# SYSCTRL_PADCONF_CORE register map
Vendor: Texas Instruments
Registers are 32-bit, access per field, reset 0x10F010F unless marked. A register's access mark holds for its fields unless they carry their own. Offsets are as the file gives them; [hi:lo] are bit positions; 'fields as' and 'values as' point back to an identical list.

## SYSCTRL_PADCONF_CORE (part 5 of 10)
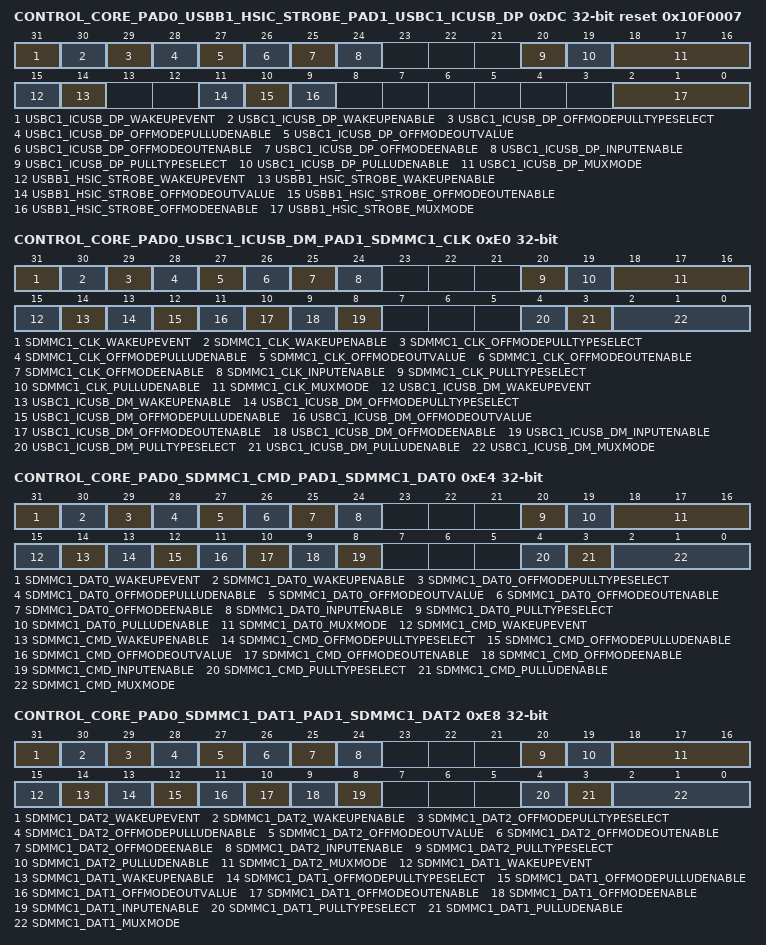
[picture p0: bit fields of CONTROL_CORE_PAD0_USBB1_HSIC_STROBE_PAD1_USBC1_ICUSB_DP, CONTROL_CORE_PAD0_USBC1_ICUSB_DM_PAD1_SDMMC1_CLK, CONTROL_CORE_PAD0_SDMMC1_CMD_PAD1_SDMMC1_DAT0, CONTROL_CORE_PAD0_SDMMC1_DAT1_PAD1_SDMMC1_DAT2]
0xDC CONTROL_CORE_PAD0_USBB1_HSIC_STROBE_PAD1_USBC1_ICUSB_DP reset 0x10F0007 — Register control for Pads usbb1_hsic_strobe and usbc1_icusb_dp Access conditions. Read: unrestricted, Write: unrestricted
  [31] USBC1_ICUSB_DP_WAKEUPEVENT ro — Pad_x wake-up event status latched in the IO
    0=USBC1_ICUSB_DP_WAKEUPEVENT_0_r (No wake-up event occurred); 1=USBC1_ICUSB_DP_WAKEUPEVENT_1_r (A wake-up event occurred)
  [30] USBC1_ICUSB_DP_WAKEUPENABLE rw — Input pad wake-up enable (and OFF mode input enable value)
    0=wake-up detection is disabled; 1=wake-up detection is enabled
  [29] USBC1_ICUSB_DP_OFFMODEPULLTYPESELECT rw — OffMode mode pullup/down selection for pad usbc1_icusb_dp
    0=Offmode pulldown selected; 1=Offmode pullup selected
  [28] USBC1_ICUSB_DP_OFFMODEPULLUDENABLE rw — OffMode mode pullup/down enable for pad usbc1_icusb_dp
    0=Offmode pullup/down disabled; 1=Offmode pullup/down enabled
  [27] USBC1_ICUSB_DP_OFFMODEOUTVALUE rw — OffMode mode output value for pad usbc1_icusb_dp
    0=Set value at 0; 1=Set value at 1
  [26] USBC1_ICUSB_DP_OFFMODEOUTENABLE rw — OffMode mode output enable value for pad usbc1_icusb_dp. This is an active low signal
    0=Output enable; 1=Output disable
  [25] USBC1_ICUSB_DP_OFFMODEENABLE rw — OffMode mode override control for pad usbc1_icusb_dp
    0=I/O state keeps its previous state when OFF mode is active; 1=I/O state is forced to OFF mode value when OFF mode is active
  [24] USBC1_ICUSB_DP_INPUTENABLE rw — Input enable value for pad usbc1_icusb_dp
    0=Input buffer of I/O cell is disabled; 1=Input buffer of I/O cell is enabled
  [20] USBC1_ICUSB_DP_PULLTYPESELECT rw — pullup/down selection for pad usbc1_icusb_dp
    0=pulldown selected; 1=pullup selected
  [19] USBC1_ICUSB_DP_PULLUDENABLE rw — pullup/down enable for pad usbc1_icusb_dp
    0=pullup/down disabled; 1=pullup/down enabled
  [18:16] USBC1_ICUSB_DP_MUXMODE rw — Functional multiplexing selection for pad usbc1_icusb_dp
    0=Select usbc1_icusb_dp; 3=Select gpio_98; 7=Select safe_mode
  [15] USBB1_HSIC_STROBE_WAKEUPEVENT ro — Pad_x wake-up event status latched in the IO
    0=USBB1_HSIC_STROBE_WAKEUPEVENT_0_r (No wake-up event occurred); 1=USBB1_HSIC_STROBE_WAKEUPEVENT_1_r (A wake-up event occurred)
  [14] USBB1_HSIC_STROBE_WAKEUPENABLE rw — Input pad wake-up enable (and OFF mode input enable value)
    values as USBC1_ICUSB_DP_WAKEUPENABLE
  [11] USBB1_HSIC_STROBE_OFFMODEOUTVALUE rw — OffMode mode output value for pad usbb1_hsic_strobe
    0=Set value at 0; 1=Set value at 1
  [10] USBB1_HSIC_STROBE_OFFMODEOUTENABLE rw — OffMode mode output enable value for pad usbb1_hsic_strobe. This is an active low signal
    0=Output enable; 1=Output disable
  [9] USBB1_HSIC_STROBE_OFFMODEENABLE rw — OffMode mode override control for pad usbb1_hsic_strobe
    values as USBC1_ICUSB_DP_OFFMODEENABLE
  [2:0] USBB1_HSIC_STROBE_MUXMODE rw — Functional multiplexing selection for pad usbb1_hsic_strobe
    0=Select usbb1_hsic_strobe; 3=Select gpio_97; 7=Select safe_mode
0xE0 CONTROL_CORE_PAD0_USBC1_ICUSB_DM_PAD1_SDMMC1_CLK — Register control for Pads usbc1_icusb_dm and sdmmc1_clk Access conditions. Read: unrestricted, Write: unrestricted
  [31] SDMMC1_CLK_WAKEUPEVENT ro — Pad_x wake-up event status latched in the IO
    0=SDMMC1_CLK_WAKEUPEVENT_0_r (No wake-up event occurred); 1=SDMMC1_CLK_WAKEUPEVENT_1_r (A wake-up event occurred)
  [30] SDMMC1_CLK_WAKEUPENABLE rw — Input pad wake-up enable (and OFF mode input enable value)
    values as CONTROL_CORE_PAD0_USBB1_HSIC_STROBE_PAD1_USBC1_ICUSB_DP.USBC1_ICUSB_DP_WAKEUPENABLE
  [29] SDMMC1_CLK_OFFMODEPULLTYPESELECT rw — OffMode mode pullup/down selection for pad sdmmc1_clk
    0=Offmode pulldown selected; 1=Offmode pullup selected
  [28] SDMMC1_CLK_OFFMODEPULLUDENABLE rw — OffMode mode pullup/down enable for pad sdmmc1_clk
    values as CONTROL_CORE_PAD0_USBB1_HSIC_STROBE_PAD1_USBC1_ICUSB_DP.USBC1_ICUSB_DP_OFFMODEPULLUDENABLE
  [27] SDMMC1_CLK_OFFMODEOUTVALUE rw — OffMode mode output value for pad sdmmc1_clk
    0=Set value at 0; 1=Set value at 1
  [26] SDMMC1_CLK_OFFMODEOUTENABLE rw — OffMode mode output enable value for pad sdmmc1_clk. This is an active low signal
    0=Output enable; 1=Output disable
  [25] SDMMC1_CLK_OFFMODEENABLE rw — OffMode mode override control for pad sdmmc1_clk
    values as CONTROL_CORE_PAD0_USBB1_HSIC_STROBE_PAD1_USBC1_ICUSB_DP.USBC1_ICUSB_DP_OFFMODEENABLE
  [24] SDMMC1_CLK_INPUTENABLE rw — Input enable value for pad sdmmc1_clk
    values as CONTROL_CORE_PAD0_USBB1_HSIC_STROBE_PAD1_USBC1_ICUSB_DP.USBC1_ICUSB_DP_INPUTENABLE
  [20] SDMMC1_CLK_PULLTYPESELECT rw — pullup/down selection for pad sdmmc1_clk
    0=pulldown selected; 1=pullup selected
  [19] SDMMC1_CLK_PULLUDENABLE rw — pullup/down enable for pad sdmmc1_clk
    0=pullup/down disabled; 1=pullup/down enabled
  [18:16] SDMMC1_CLK_MUXMODE rw — Functional multiplexing selection for pad sdmmc1_clk
    0=Select sdmmc1_clk; 2=Select dpm_emu19; 3=Select gpio_100; 7=Select safe_mode
  [15] USBC1_ICUSB_DM_WAKEUPEVENT ro — Pad_x wake-up event status latched in the IO
    0=USBC1_ICUSB_DM_WAKEUPEVENT_0_r (No wake-up event occurred); 1=USBC1_ICUSB_DM_WAKEUPEVENT_1_r (A wake-up event occurred)
  [14] USBC1_ICUSB_DM_WAKEUPENABLE rw — Input pad wake-up enable (and OFF mode input enable value)
    values as CONTROL_CORE_PAD0_USBB1_HSIC_STROBE_PAD1_USBC1_ICUSB_DP.USBC1_ICUSB_DP_WAKEUPENABLE
  [13] USBC1_ICUSB_DM_OFFMODEPULLTYPESELECT rw — OffMode mode pullup/down selection for pad usbc1_icusb_dm
    0=Offmode pulldown selected; 1=Offmode pullup selected
  [12] USBC1_ICUSB_DM_OFFMODEPULLUDENABLE rw — OffMode mode pullup/down enable for pad usbc1_icusb_dm
    values as CONTROL_CORE_PAD0_USBB1_HSIC_STROBE_PAD1_USBC1_ICUSB_DP.USBC1_ICUSB_DP_OFFMODEPULLUDENABLE
  [11] USBC1_ICUSB_DM_OFFMODEOUTVALUE rw — OffMode mode output value for pad usbc1_icusb_dm
    0=Set value at 0; 1=Set value at 1
  [10] USBC1_ICUSB_DM_OFFMODEOUTENABLE rw — OffMode mode output enable value for pad usbc1_icusb_dm. This is an active low signal
    0=Output enable; 1=Output disable
  [9] USBC1_ICUSB_DM_OFFMODEENABLE rw — OffMode mode override control for pad usbc1_icusb_dm
    values as CONTROL_CORE_PAD0_USBB1_HSIC_STROBE_PAD1_USBC1_ICUSB_DP.USBC1_ICUSB_DP_OFFMODEENABLE
  [8] USBC1_ICUSB_DM_INPUTENABLE rw — Input enable value for pad usbc1_icusb_dm
    values as CONTROL_CORE_PAD0_USBB1_HSIC_STROBE_PAD1_USBC1_ICUSB_DP.USBC1_ICUSB_DP_INPUTENABLE
  [4] USBC1_ICUSB_DM_PULLTYPESELECT rw — pullup/down selection for pad usbc1_icusb_dm
    0=pulldown selected; 1=pullup selected
  [3] USBC1_ICUSB_DM_PULLUDENABLE rw — pullup/down enable for pad usbc1_icusb_dm
    0=pullup/down disabled; 1=pullup/down enabled
  [2:0] USBC1_ICUSB_DM_MUXMODE rw — Functional multiplexing selection for pad usbc1_icusb_dm
    0=Select usbc1_icusb_dm; 3=Select gpio_99; 7=Select safe_mode
0xE4 CONTROL_CORE_PAD0_SDMMC1_CMD_PAD1_SDMMC1_DAT0 — Register control for Pads sdmmc1_cmd and sdmmc1_dat0 Access conditions. Read: unrestricted, Write: unrestricted
  [31] SDMMC1_DAT0_WAKEUPEVENT ro — Pad_x wake-up event status latched in the IO
    0=SDMMC1_DAT0_WAKEUPEVENT_0_r (No wake-up event occurred); 1=SDMMC1_DAT0_WAKEUPEVENT_1_r (A wake-up event occurred)
  [30] SDMMC1_DAT0_WAKEUPENABLE rw — Input pad wake-up enable (and OFF mode input enable value)
    values as CONTROL_CORE_PAD0_USBB1_HSIC_STROBE_PAD1_USBC1_ICUSB_DP.USBC1_ICUSB_DP_WAKEUPENABLE
  [29] SDMMC1_DAT0_OFFMODEPULLTYPESELECT rw — OffMode mode pullup/down selection for pad sdmmc1_dat0
    0=Offmode pulldown selected; 1=Offmode pullup selected
  [28] SDMMC1_DAT0_OFFMODEPULLUDENABLE rw — OffMode mode pullup/down enable for pad sdmmc1_dat0
    values as CONTROL_CORE_PAD0_USBB1_HSIC_STROBE_PAD1_USBC1_ICUSB_DP.USBC1_ICUSB_DP_OFFMODEPULLUDENABLE
  [27] SDMMC1_DAT0_OFFMODEOUTVALUE rw — OffMode mode output value for pad sdmmc1_dat0
    0=Set value at 0; 1=Set value at 1
  [26] SDMMC1_DAT0_OFFMODEOUTENABLE rw — OffMode mode output enable value for pad sdmmc1_dat0. This is an active low signal
    0=Output enable; 1=Output disable
  [25] SDMMC1_DAT0_OFFMODEENABLE rw — OffMode mode override control for pad sdmmc1_dat0
    values as CONTROL_CORE_PAD0_USBB1_HSIC_STROBE_PAD1_USBC1_ICUSB_DP.USBC1_ICUSB_DP_OFFMODEENABLE
  [24] SDMMC1_DAT0_INPUTENABLE rw — Input enable value for pad sdmmc1_dat0
    values as CONTROL_CORE_PAD0_USBB1_HSIC_STROBE_PAD1_USBC1_ICUSB_DP.USBC1_ICUSB_DP_INPUTENABLE
  [20] SDMMC1_DAT0_PULLTYPESELECT rw — pullup/down selection for pad sdmmc1_dat0
    0=pulldown selected; 1=pullup selected
  [19] SDMMC1_DAT0_PULLUDENABLE rw — pullup/down enable for pad sdmmc1_dat0
    0=pullup/down disabled; 1=pullup/down enabled
  [18:16] SDMMC1_DAT0_MUXMODE rw — Functional multiplexing selection for pad sdmmc1_dat0
    0=Select sdmmc1_dat0; 2=Select dpm_emu18; 3=Select gpio_102; 7=Select safe_mode
  [15] SDMMC1_CMD_WAKEUPEVENT ro — Pad_x wake-up event status latched in the IO
    0=SDMMC1_CMD_WAKEUPEVENT_0_r (No wake-up event occurred); 1=SDMMC1_CMD_WAKEUPEVENT_1_r (A wake-up event occurred)
  [14] SDMMC1_CMD_WAKEUPENABLE rw — Input pad wake-up enable (and OFF mode input enable value)
    values as CONTROL_CORE_PAD0_USBB1_HSIC_STROBE_PAD1_USBC1_ICUSB_DP.USBC1_ICUSB_DP_WAKEUPENABLE
  [13] SDMMC1_CMD_OFFMODEPULLTYPESELECT rw — OffMode mode pullup/down selection for pad sdmmc1_cmd
    0=Offmode pulldown selected; 1=Offmode pullup selected
  [12] SDMMC1_CMD_OFFMODEPULLUDENABLE rw — OffMode mode pullup/down enable for pad sdmmc1_cmd
    values as CONTROL_CORE_PAD0_USBB1_HSIC_STROBE_PAD1_USBC1_ICUSB_DP.USBC1_ICUSB_DP_OFFMODEPULLUDENABLE
  [11] SDMMC1_CMD_OFFMODEOUTVALUE rw — OffMode mode output value for pad sdmmc1_cmd
    0=Set value at 0; 1=Set value at 1
  [10] SDMMC1_CMD_OFFMODEOUTENABLE rw — OffMode mode output enable value for pad sdmmc1_cmd. This is an active low signal
    0=Output enable; 1=Output disable
  [9] SDMMC1_CMD_OFFMODEENABLE rw — OffMode mode override control for pad sdmmc1_cmd
    values as CONTROL_CORE_PAD0_USBB1_HSIC_STROBE_PAD1_USBC1_ICUSB_DP.USBC1_ICUSB_DP_OFFMODEENABLE
  [8] SDMMC1_CMD_INPUTENABLE rw — Input enable value for pad sdmmc1_cmd
    values as CONTROL_CORE_PAD0_USBB1_HSIC_STROBE_PAD1_USBC1_ICUSB_DP.USBC1_ICUSB_DP_INPUTENABLE
  [4] SDMMC1_CMD_PULLTYPESELECT rw — pullup/down selection for pad sdmmc1_cmd
    0=pulldown selected; 1=pullup selected
  [3] SDMMC1_CMD_PULLUDENABLE rw — pullup/down enable for pad sdmmc1_cmd
    0=pullup/down disabled; 1=pullup/down enabled
  [2:0] SDMMC1_CMD_MUXMODE rw — Functional multiplexing selection for pad sdmmc1_cmd
    0=Select sdmmc1_cmd; 2=Select uart1_rx; 3=Select gpio_101; 7=Select safe_mode
0xE8 CONTROL_CORE_PAD0_SDMMC1_DAT1_PAD1_SDMMC1_DAT2 — Register control for Pads sdmmc1_dat1 and sdmmc1_dat2 Access conditions. Read: unrestricted, Write: unrestricted
  [31] SDMMC1_DAT2_WAKEUPEVENT ro — Pad_x wake-up event status latched in the IO
    0=SDMMC1_DAT2_WAKEUPEVENT_0_r (No wake-up event occurred); 1=SDMMC1_DAT2_WAKEUPEVENT_1_r (A wake-up event occurred)
  [30] SDMMC1_DAT2_WAKEUPENABLE rw — Input pad wake-up enable (and OFF mode input enable value)
    values as CONTROL_CORE_PAD0_USBB1_HSIC_STROBE_PAD1_USBC1_ICUSB_DP.USBC1_ICUSB_DP_WAKEUPENABLE
  [29] SDMMC1_DAT2_OFFMODEPULLTYPESELECT rw — OffMode mode pullup/down selection for pad sdmmc1_dat2
    0=Offmode pulldown selected; 1=Offmode pullup selected
  [28] SDMMC1_DAT2_OFFMODEPULLUDENABLE rw — OffMode mode pullup/down enable for pad sdmmc1_dat2
    values as CONTROL_CORE_PAD0_USBB1_HSIC_STROBE_PAD1_USBC1_ICUSB_DP.USBC1_ICUSB_DP_OFFMODEPULLUDENABLE
  [27] SDMMC1_DAT2_OFFMODEOUTVALUE rw — OffMode mode output value for pad sdmmc1_dat2
    0=Set value at 0; 1=Set value at 1
  [26] SDMMC1_DAT2_OFFMODEOUTENABLE rw — OffMode mode output enable value for pad sdmmc1_dat2. This is an active low signal
    0=Output enable; 1=Output disable
  [25] SDMMC1_DAT2_OFFMODEENABLE rw — OffMode mode override control for pad sdmmc1_dat2
    values as CONTROL_CORE_PAD0_USBB1_HSIC_STROBE_PAD1_USBC1_ICUSB_DP.USBC1_ICUSB_DP_OFFMODEENABLE
  [24] SDMMC1_DAT2_INPUTENABLE rw — Input enable value for pad sdmmc1_dat2
    values as CONTROL_CORE_PAD0_USBB1_HSIC_STROBE_PAD1_USBC1_ICUSB_DP.USBC1_ICUSB_DP_INPUTENABLE
  [20] SDMMC1_DAT2_PULLTYPESELECT rw — pullup/down selection for pad sdmmc1_dat2
    0=pulldown selected; 1=pullup selected
  [19] SDMMC1_DAT2_PULLUDENABLE rw — pullup/down enable for pad sdmmc1_dat2
    0=pullup/down disabled; 1=pullup/down enabled
  [18:16] SDMMC1_DAT2_MUXMODE rw — Functional multiplexing selection for pad sdmmc1_dat2
    0=Select sdmmc1_dat2; 2=Select dpm_emu16; 3=Select gpio_104; 4=Select jtag_tms_tmsc; 7=Select safe_mode
  [15] SDMMC1_DAT1_WAKEUPEVENT ro — Pad_x wake-up event status latched in the IO
    0=SDMMC1_DAT1_WAKEUPEVENT_0_r (No wake-up event occurred); 1=SDMMC1_DAT1_WAKEUPEVENT_1_r (A wake-up event occurred)
  [14] SDMMC1_DAT1_WAKEUPENABLE rw — Input pad wake-up enable (and OFF mode input enable value)
    values as CONTROL_CORE_PAD0_USBB1_HSIC_STROBE_PAD1_USBC1_ICUSB_DP.USBC1_ICUSB_DP_WAKEUPENABLE
  [13] SDMMC1_DAT1_OFFMODEPULLTYPESELECT rw — OffMode mode pullup/down selection for pad sdmmc1_dat1
    0=Offmode pulldown selected; 1=Offmode pullup selected
  [12] SDMMC1_DAT1_OFFMODEPULLUDENABLE rw — OffMode mode pullup/down enable for pad sdmmc1_dat1
    values as CONTROL_CORE_PAD0_USBB1_HSIC_STROBE_PAD1_USBC1_ICUSB_DP.USBC1_ICUSB_DP_OFFMODEPULLUDENABLE
  [11] SDMMC1_DAT1_OFFMODEOUTVALUE rw — OffMode mode output value for pad sdmmc1_dat1
    0=Set value at 0; 1=Set value at 1
  [10] SDMMC1_DAT1_OFFMODEOUTENABLE rw — OffMode mode output enable value for pad sdmmc1_dat1. This is an active low signal
    0=Output enable; 1=Output disable
  [9] SDMMC1_DAT1_OFFMODEENABLE rw — OffMode mode override control for pad sdmmc1_dat1
    values as CONTROL_CORE_PAD0_USBB1_HSIC_STROBE_PAD1_USBC1_ICUSB_DP.USBC1_ICUSB_DP_OFFMODEENABLE
  [8] SDMMC1_DAT1_INPUTENABLE rw — Input enable value for pad sdmmc1_dat1
    values as CONTROL_CORE_PAD0_USBB1_HSIC_STROBE_PAD1_USBC1_ICUSB_DP.USBC1_ICUSB_DP_INPUTENABLE
  [4] SDMMC1_DAT1_PULLTYPESELECT rw — pullup/down selection for pad sdmmc1_dat1
    0=pulldown selected; 1=pullup selected
  [3] SDMMC1_DAT1_PULLUDENABLE rw — pullup/down enable for pad sdmmc1_dat1
    0=pullup/down disabled; 1=pullup/down enabled
  [2:0] SDMMC1_DAT1_MUXMODE rw — Functional multiplexing selection for pad sdmmc1_dat1
    0=Select sdmmc1_dat1; 2=Select dpm_emu17; 3=Select gpio_103; 7=Select safe_mode
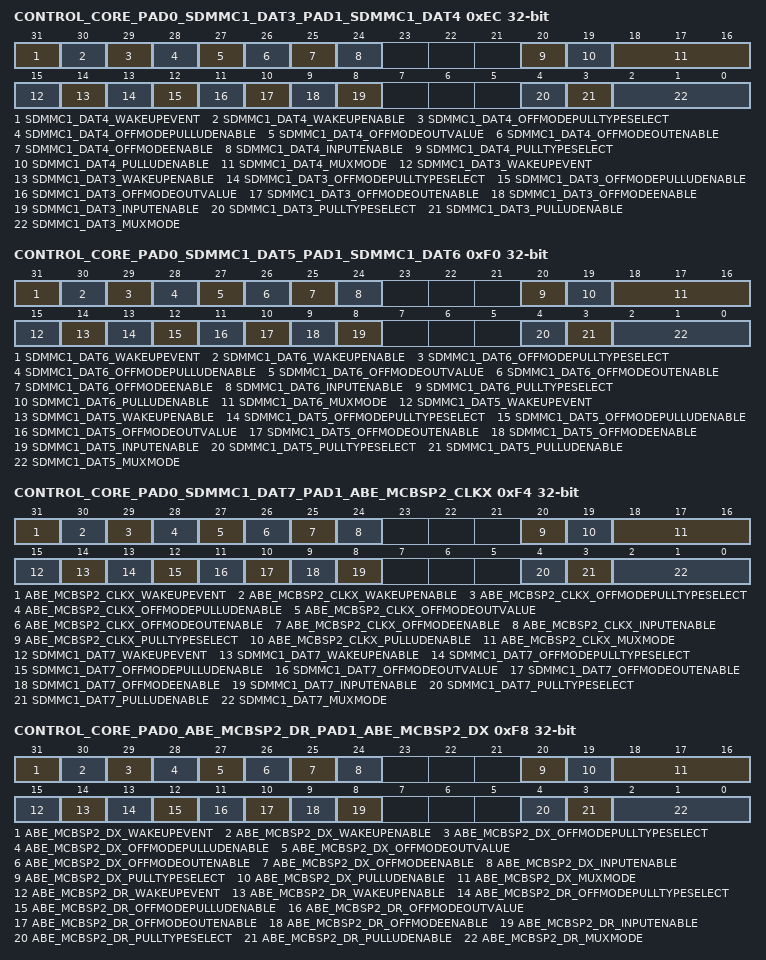
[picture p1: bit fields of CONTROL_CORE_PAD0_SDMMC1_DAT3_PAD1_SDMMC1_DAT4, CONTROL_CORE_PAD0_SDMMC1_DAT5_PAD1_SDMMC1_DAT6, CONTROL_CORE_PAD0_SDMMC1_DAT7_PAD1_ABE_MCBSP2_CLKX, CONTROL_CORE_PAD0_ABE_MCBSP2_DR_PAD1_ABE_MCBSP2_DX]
0xEC CONTROL_CORE_PAD0_SDMMC1_DAT3_PAD1_SDMMC1_DAT4 — Register control for Pads sdmmc1_dat3 and sdmmc1_dat4 Access conditions. Read: unrestricted, Write: unrestricted
  [31] SDMMC1_DAT4_WAKEUPEVENT ro — Pad_x wake-up event status latched in the IO
    0=SDMMC1_DAT4_WAKEUPEVENT_0_r (No wake-up event occurred); 1=SDMMC1_DAT4_WAKEUPEVENT_1_r (A wake-up event occurred)
  [30] SDMMC1_DAT4_WAKEUPENABLE rw — Input pad wake-up enable (and OFF mode input enable value)
    values as CONTROL_CORE_PAD0_USBB1_HSIC_STROBE_PAD1_USBC1_ICUSB_DP.USBC1_ICUSB_DP_WAKEUPENABLE
  [29] SDMMC1_DAT4_OFFMODEPULLTYPESELECT rw — OffMode mode pullup/down selection for pad sdmmc1_dat4
    0=Offmode pulldown selected; 1=Offmode pullup selected
  [28] SDMMC1_DAT4_OFFMODEPULLUDENABLE rw — OffMode mode pullup/down enable for pad sdmmc1_dat4
    values as CONTROL_CORE_PAD0_USBB1_HSIC_STROBE_PAD1_USBC1_ICUSB_DP.USBC1_ICUSB_DP_OFFMODEPULLUDENABLE
  [27] SDMMC1_DAT4_OFFMODEOUTVALUE rw — OffMode mode output value for pad sdmmc1_dat4
    0=Set value at 0; 1=Set value at 1
  [26] SDMMC1_DAT4_OFFMODEOUTENABLE rw — OffMode mode output enable value for pad sdmmc1_dat4. This is an active low signal
    0=Output enable; 1=Output disable
  [25] SDMMC1_DAT4_OFFMODEENABLE rw — OffMode mode override control for pad sdmmc1_dat4
    values as CONTROL_CORE_PAD0_USBB1_HSIC_STROBE_PAD1_USBC1_ICUSB_DP.USBC1_ICUSB_DP_OFFMODEENABLE
  [24] SDMMC1_DAT4_INPUTENABLE rw — Input enable value for pad sdmmc1_dat4
    values as CONTROL_CORE_PAD0_USBB1_HSIC_STROBE_PAD1_USBC1_ICUSB_DP.USBC1_ICUSB_DP_INPUTENABLE
  [20] SDMMC1_DAT4_PULLTYPESELECT rw — pullup/down selection for pad sdmmc1_dat4
    0=pulldown selected; 1=pullup selected
  [19] SDMMC1_DAT4_PULLUDENABLE rw — pullup/down enable for pad sdmmc1_dat4
    0=pullup/down disabled; 1=pullup/down enabled
  [18:16] SDMMC1_DAT4_MUXMODE rw — Functional multiplexing selection for pad sdmmc1_dat4
    0=Select sdmmc1_dat4; 3=Select gpio_106; 7=Select safe_mode
  [15] SDMMC1_DAT3_WAKEUPEVENT ro — Pad_x wake-up event status latched in the IO
    0=SDMMC1_DAT3_WAKEUPEVENT_0_r (No wake-up event occurred); 1=SDMMC1_DAT3_WAKEUPEVENT_1_r (A wake-up event occurred)
  [14] SDMMC1_DAT3_WAKEUPENABLE rw — Input pad wake-up enable (and OFF mode input enable value)
    values as CONTROL_CORE_PAD0_USBB1_HSIC_STROBE_PAD1_USBC1_ICUSB_DP.USBC1_ICUSB_DP_WAKEUPENABLE
  [13] SDMMC1_DAT3_OFFMODEPULLTYPESELECT rw — OffMode mode pullup/down selection for pad sdmmc1_dat3
    0=Offmode pulldown selected; 1=Offmode pullup selected
  [12] SDMMC1_DAT3_OFFMODEPULLUDENABLE rw — OffMode mode pullup/down enable for pad sdmmc1_dat3
    values as CONTROL_CORE_PAD0_USBB1_HSIC_STROBE_PAD1_USBC1_ICUSB_DP.USBC1_ICUSB_DP_OFFMODEPULLUDENABLE
  [11] SDMMC1_DAT3_OFFMODEOUTVALUE rw — OffMode mode output value for pad sdmmc1_dat3
    0=Set value at 0; 1=Set value at 1
  [10] SDMMC1_DAT3_OFFMODEOUTENABLE rw — OffMode mode output enable value for pad sdmmc1_dat3. This is an active low signal
    0=Output enable; 1=Output disable
  [9] SDMMC1_DAT3_OFFMODEENABLE rw — OffMode mode override control for pad sdmmc1_dat3
    values as CONTROL_CORE_PAD0_USBB1_HSIC_STROBE_PAD1_USBC1_ICUSB_DP.USBC1_ICUSB_DP_OFFMODEENABLE
  [8] SDMMC1_DAT3_INPUTENABLE rw — Input enable value for pad sdmmc1_dat3
    values as CONTROL_CORE_PAD0_USBB1_HSIC_STROBE_PAD1_USBC1_ICUSB_DP.USBC1_ICUSB_DP_INPUTENABLE
  [4] SDMMC1_DAT3_PULLTYPESELECT rw — pullup/down selection for pad sdmmc1_dat3
    0=pulldown selected; 1=pullup selected
  [3] SDMMC1_DAT3_PULLUDENABLE rw — pullup/down enable for pad sdmmc1_dat3
    0=pullup/down disabled; 1=pullup/down enabled
  [2:0] SDMMC1_DAT3_MUXMODE rw — Functional multiplexing selection for pad sdmmc1_dat3
    0=Select sdmmc1_dat3; 2=Select dpm_emu15; 3=Select gpio_105; 4=Select jtag_tck; 7=Select safe_mode
0xF0 CONTROL_CORE_PAD0_SDMMC1_DAT5_PAD1_SDMMC1_DAT6 — Register control for Pads sdmmc1_dat5 and sdmmc1_dat6 Access conditions. Read: unrestricted, Write: unrestricted
  [31] SDMMC1_DAT6_WAKEUPEVENT ro — Pad_x wake-up event status latched in the IO
    0=SDMMC1_DAT6_WAKEUPEVENT_0_r (No wake-up event occurred); 1=SDMMC1_DAT6_WAKEUPEVENT_1_r (A wake-up event occurred)
  [30] SDMMC1_DAT6_WAKEUPENABLE rw — Input pad wake-up enable (and OFF mode input enable value)
    values as CONTROL_CORE_PAD0_USBB1_HSIC_STROBE_PAD1_USBC1_ICUSB_DP.USBC1_ICUSB_DP_WAKEUPENABLE
  [29] SDMMC1_DAT6_OFFMODEPULLTYPESELECT rw — OffMode mode pullup/down selection for pad sdmmc1_dat6
    0=Offmode pulldown selected; 1=Offmode pullup selected
  [28] SDMMC1_DAT6_OFFMODEPULLUDENABLE rw — OffMode mode pullup/down enable for pad sdmmc1_dat6
    values as CONTROL_CORE_PAD0_USBB1_HSIC_STROBE_PAD1_USBC1_ICUSB_DP.USBC1_ICUSB_DP_OFFMODEPULLUDENABLE
  [27] SDMMC1_DAT6_OFFMODEOUTVALUE rw — OffMode mode output value for pad sdmmc1_dat6
    0=Set value at 0; 1=Set value at 1
  [26] SDMMC1_DAT6_OFFMODEOUTENABLE rw — OffMode mode output enable value for pad sdmmc1_dat6. This is an active low signal
    0=Output enable; 1=Output disable
  [25] SDMMC1_DAT6_OFFMODEENABLE rw — OffMode mode override control for pad sdmmc1_dat6
    values as CONTROL_CORE_PAD0_USBB1_HSIC_STROBE_PAD1_USBC1_ICUSB_DP.USBC1_ICUSB_DP_OFFMODEENABLE
  [24] SDMMC1_DAT6_INPUTENABLE rw — Input enable value for pad sdmmc1_dat6
    values as CONTROL_CORE_PAD0_USBB1_HSIC_STROBE_PAD1_USBC1_ICUSB_DP.USBC1_ICUSB_DP_INPUTENABLE
  [20] SDMMC1_DAT6_PULLTYPESELECT rw — pullup/down selection for pad sdmmc1_dat6
    0=pulldown selected; 1=pullup selected
  [19] SDMMC1_DAT6_PULLUDENABLE rw — pullup/down enable for pad sdmmc1_dat6
    0=pullup/down disabled; 1=pullup/down enabled
  [18:16] SDMMC1_DAT6_MUXMODE rw — Functional multiplexing selection for pad sdmmc1_dat6
    0=Select sdmmc1_dat6; 3=Select gpio_108; 7=Select safe_mode
  [15] SDMMC1_DAT5_WAKEUPEVENT ro — Pad_x wake-up event status latched in the IO
    0=SDMMC1_DAT5_WAKEUPEVENT_0_r (No wake-up event occurred); 1=SDMMC1_DAT5_WAKEUPEVENT_1_r (A wake-up event occurred)
  [14] SDMMC1_DAT5_WAKEUPENABLE rw — Input pad wake-up enable (and OFF mode input enable value)
    values as CONTROL_CORE_PAD0_USBB1_HSIC_STROBE_PAD1_USBC1_ICUSB_DP.USBC1_ICUSB_DP_WAKEUPENABLE
  [13] SDMMC1_DAT5_OFFMODEPULLTYPESELECT rw — OffMode mode pullup/down selection for pad sdmmc1_dat5
    0=Offmode pulldown selected; 1=Offmode pullup selected
  [12] SDMMC1_DAT5_OFFMODEPULLUDENABLE rw — OffMode mode pullup/down enable for pad sdmmc1_dat5
    values as CONTROL_CORE_PAD0_USBB1_HSIC_STROBE_PAD1_USBC1_ICUSB_DP.USBC1_ICUSB_DP_OFFMODEPULLUDENABLE
  [11] SDMMC1_DAT5_OFFMODEOUTVALUE rw — OffMode mode output value for pad sdmmc1_dat5
    0=Set value at 0; 1=Set value at 1
  [10] SDMMC1_DAT5_OFFMODEOUTENABLE rw — OffMode mode output enable value for pad sdmmc1_dat5. This is an active low signal
    0=Output enable; 1=Output disable
  [9] SDMMC1_DAT5_OFFMODEENABLE rw — OffMode mode override control for pad sdmmc1_dat5
    values as CONTROL_CORE_PAD0_USBB1_HSIC_STROBE_PAD1_USBC1_ICUSB_DP.USBC1_ICUSB_DP_OFFMODEENABLE
  [8] SDMMC1_DAT5_INPUTENABLE rw — Input enable value for pad sdmmc1_dat5
    values as CONTROL_CORE_PAD0_USBB1_HSIC_STROBE_PAD1_USBC1_ICUSB_DP.USBC1_ICUSB_DP_INPUTENABLE
  [4] SDMMC1_DAT5_PULLTYPESELECT rw — pullup/down selection for pad sdmmc1_dat5
    0=pulldown selected; 1=pullup selected
  [3] SDMMC1_DAT5_PULLUDENABLE rw — pullup/down enable for pad sdmmc1_dat5
    0=pullup/down disabled; 1=pullup/down enabled
  [2:0] SDMMC1_DAT5_MUXMODE rw — Functional multiplexing selection for pad sdmmc1_dat5
    0=Select sdmmc1_dat5; 3=Select gpio_107; 7=Select safe_mode
0xF4 CONTROL_CORE_PAD0_SDMMC1_DAT7_PAD1_ABE_MCBSP2_CLKX — Register control for Pads sdmmc1_dat7 and abe_mcbsp2_clkx Access conditions. Read: unrestricted, Write: unrestricted
  [31] ABE_MCBSP2_CLKX_WAKEUPEVENT ro — Pad_x wake-up event status latched in the IO
    0=ABE_MCBSP2_CLKX_WAKEUPEVENT_0_r (No wake-up event occurred); 1=ABE_MCBSP2_CLKX_WAKEUPEVENT_1_r (A wake-up event occurred)
  [30] ABE_MCBSP2_CLKX_WAKEUPENABLE rw — Input pad wake-up enable (and OFF mode input enable value)
    values as CONTROL_CORE_PAD0_USBB1_HSIC_STROBE_PAD1_USBC1_ICUSB_DP.USBC1_ICUSB_DP_WAKEUPENABLE
  [29] ABE_MCBSP2_CLKX_OFFMODEPULLTYPESELECT rw — OffMode mode pullup/down selection for pad abe_mcbsp2_clkx
    0=Offmode pulldown selected; 1=Offmode pullup selected
  [28] ABE_MCBSP2_CLKX_OFFMODEPULLUDENABLE rw — OffMode mode pullup/down enable for pad abe_mcbsp2_clkx
    values as CONTROL_CORE_PAD0_USBB1_HSIC_STROBE_PAD1_USBC1_ICUSB_DP.USBC1_ICUSB_DP_OFFMODEPULLUDENABLE
  [27] ABE_MCBSP2_CLKX_OFFMODEOUTVALUE rw — OffMode mode output value for pad abe_mcbsp2_clkx
    0=Set value at 0; 1=Set value at 1
  [26] ABE_MCBSP2_CLKX_OFFMODEOUTENABLE rw — OffMode mode output enable value for pad abe_mcbsp2_clkx. This is an active low signal
    0=Output enable; 1=Output disable
  [25] ABE_MCBSP2_CLKX_OFFMODEENABLE rw — OffMode mode override control for pad abe_mcbsp2_clkx
    values as CONTROL_CORE_PAD0_USBB1_HSIC_STROBE_PAD1_USBC1_ICUSB_DP.USBC1_ICUSB_DP_OFFMODEENABLE
  [24] ABE_MCBSP2_CLKX_INPUTENABLE rw — Input enable value for pad abe_mcbsp2_clkx
    values as CONTROL_CORE_PAD0_USBB1_HSIC_STROBE_PAD1_USBC1_ICUSB_DP.USBC1_ICUSB_DP_INPUTENABLE
  [20] ABE_MCBSP2_CLKX_PULLTYPESELECT rw — pullup/down selection for pad abe_mcbsp2_clkx
    0=pulldown selected; 1=pullup selected
  [19] ABE_MCBSP2_CLKX_PULLUDENABLE rw — pullup/down enable for pad abe_mcbsp2_clkx
    0=pullup/down disabled; 1=pullup/down enabled
  [18:16] ABE_MCBSP2_CLKX_MUXMODE rw — Functional multiplexing selection for pad abe_mcbsp2_clkx
    0=Select abe_mcbsp2_clkx; 1=Select mcspi2_clk; 2=Select abe_mcasp_ahclkx; 3=Select gpio_110; 4=Select usbb2_mm_rxdm; 7=Select safe_mode
  [15] SDMMC1_DAT7_WAKEUPEVENT ro — Pad_x wake-up event status latched in the IO
    0=SDMMC1_DAT7_WAKEUPEVENT_0_r (No wake-up event occurred); 1=SDMMC1_DAT7_WAKEUPEVENT_1_r (A wake-up event occurred)
  [14] SDMMC1_DAT7_WAKEUPENABLE rw — Input pad wake-up enable (and OFF mode input enable value)
    values as CONTROL_CORE_PAD0_USBB1_HSIC_STROBE_PAD1_USBC1_ICUSB_DP.USBC1_ICUSB_DP_WAKEUPENABLE
  [13] SDMMC1_DAT7_OFFMODEPULLTYPESELECT rw — OffMode mode pullup/down selection for pad sdmmc1_dat7
    0=Offmode pulldown selected; 1=Offmode pullup selected
  [12] SDMMC1_DAT7_OFFMODEPULLUDENABLE rw — OffMode mode pullup/down enable for pad sdmmc1_dat7
    values as CONTROL_CORE_PAD0_USBB1_HSIC_STROBE_PAD1_USBC1_ICUSB_DP.USBC1_ICUSB_DP_OFFMODEPULLUDENABLE
  [11] SDMMC1_DAT7_OFFMODEOUTVALUE rw — OffMode mode output value for pad sdmmc1_dat7
    0=Set value at 0; 1=Set value at 1
  [10] SDMMC1_DAT7_OFFMODEOUTENABLE rw — OffMode mode output enable value for pad sdmmc1_dat7. This is an active low signal
    0=Output enable; 1=Output disable
  [9] SDMMC1_DAT7_OFFMODEENABLE rw — OffMode mode override control for pad sdmmc1_dat7
    values as CONTROL_CORE_PAD0_USBB1_HSIC_STROBE_PAD1_USBC1_ICUSB_DP.USBC1_ICUSB_DP_OFFMODEENABLE
  [8] SDMMC1_DAT7_INPUTENABLE rw — Input enable value for pad sdmmc1_dat7
    values as CONTROL_CORE_PAD0_USBB1_HSIC_STROBE_PAD1_USBC1_ICUSB_DP.USBC1_ICUSB_DP_INPUTENABLE
  [4] SDMMC1_DAT7_PULLTYPESELECT rw — pullup/down selection for pad sdmmc1_dat7
    0=pulldown selected; 1=pullup selected
  [3] SDMMC1_DAT7_PULLUDENABLE rw — pullup/down enable for pad sdmmc1_dat7
    0=pullup/down disabled; 1=pullup/down enabled
  [2:0] SDMMC1_DAT7_MUXMODE rw — Functional multiplexing selection for pad sdmmc1_dat7
    0=Select sdmmc1_dat7; 3=Select gpio_109; 7=Select safe_mode
0xF8 CONTROL_CORE_PAD0_ABE_MCBSP2_DR_PAD1_ABE_MCBSP2_DX — Register control for Pads abe_mcbsp2_dr and abe_mcbsp2_dx Access conditions. Read: unrestricted, Write: unrestricted
  [31] ABE_MCBSP2_DX_WAKEUPEVENT ro — Pad_x wake-up event status latched in the IO
    0=ABE_MCBSP2_DX_WAKEUPEVENT_0_r (No wake-up event occurred); 1=ABE_MCBSP2_DX_WAKEUPEVENT_1_r (A wake-up event occurred)
  [30] ABE_MCBSP2_DX_WAKEUPENABLE rw — Input pad wake-up enable (and OFF mode input enable value)
    values as CONTROL_CORE_PAD0_USBB1_HSIC_STROBE_PAD1_USBC1_ICUSB_DP.USBC1_ICUSB_DP_WAKEUPENABLE
  [29] ABE_MCBSP2_DX_OFFMODEPULLTYPESELECT rw — OffMode mode pullup/down selection for pad abe_mcbsp2_dx
    0=Offmode pulldown selected; 1=Offmode pullup selected
  [28] ABE_MCBSP2_DX_OFFMODEPULLUDENABLE rw — OffMode mode pullup/down enable for pad abe_mcbsp2_dx
    values as CONTROL_CORE_PAD0_USBB1_HSIC_STROBE_PAD1_USBC1_ICUSB_DP.USBC1_ICUSB_DP_OFFMODEPULLUDENABLE
  [27] ABE_MCBSP2_DX_OFFMODEOUTVALUE rw — OffMode mode output value for pad abe_mcbsp2_dx
    0=Set value at 0; 1=Set value at 1
  [26] ABE_MCBSP2_DX_OFFMODEOUTENABLE rw — OffMode mode output enable value for pad abe_mcbsp2_dx. This is an active low signal
    0=Output enable; 1=Output disable
  [25] ABE_MCBSP2_DX_OFFMODEENABLE rw — OffMode mode override control for pad abe_mcbsp2_dx
    values as CONTROL_CORE_PAD0_USBB1_HSIC_STROBE_PAD1_USBC1_ICUSB_DP.USBC1_ICUSB_DP_OFFMODEENABLE
  [24] ABE_MCBSP2_DX_INPUTENABLE rw — Input enable value for pad abe_mcbsp2_dx
    values as CONTROL_CORE_PAD0_USBB1_HSIC_STROBE_PAD1_USBC1_ICUSB_DP.USBC1_ICUSB_DP_INPUTENABLE
  [20] ABE_MCBSP2_DX_PULLTYPESELECT rw — pullup/down selection for pad abe_mcbsp2_dx
    0=pulldown selected; 1=pullup selected
  [19] ABE_MCBSP2_DX_PULLUDENABLE rw — pullup/down enable for pad abe_mcbsp2_dx
    0=pullup/down disabled; 1=pullup/down enabled
  [18:16] ABE_MCBSP2_DX_MUXMODE rw — Functional multiplexing selection for pad abe_mcbsp2_dx
    0=Select abe_mcbsp2_dx; 1=Select mcspi2_simo; 2=Select abe_mcasp_amute; 3=Select gpio_112; 4=Select usbb2_mm_rxrcv; 7=Select safe_mode
  [15] ABE_MCBSP2_DR_WAKEUPEVENT ro — Pad_x wake-up event status latched in the IO
    0=ABE_MCBSP2_DR_WAKEUPEVENT_0_r (No wake-up event occurred); 1=ABE_MCBSP2_DR_WAKEUPEVENT_1_r (A wake-up event occurred)
  [14] ABE_MCBSP2_DR_WAKEUPENABLE rw — Input pad wake-up enable (and OFF mode input enable value)
    values as CONTROL_CORE_PAD0_USBB1_HSIC_STROBE_PAD1_USBC1_ICUSB_DP.USBC1_ICUSB_DP_WAKEUPENABLE
  [13] ABE_MCBSP2_DR_OFFMODEPULLTYPESELECT rw — OffMode mode pullup/down selection for pad abe_mcbsp2_dr
    0=Offmode pulldown selected; 1=Offmode pullup selected
  [12] ABE_MCBSP2_DR_OFFMODEPULLUDENABLE rw — OffMode mode pullup/down enable for pad abe_mcbsp2_dr
    values as CONTROL_CORE_PAD0_USBB1_HSIC_STROBE_PAD1_USBC1_ICUSB_DP.USBC1_ICUSB_DP_OFFMODEPULLUDENABLE
  [11] ABE_MCBSP2_DR_OFFMODEOUTVALUE rw — OffMode mode output value for pad abe_mcbsp2_dr
    0=Set value at 0; 1=Set value at 1
  [10] ABE_MCBSP2_DR_OFFMODEOUTENABLE rw — OffMode mode output enable value for pad abe_mcbsp2_dr. This is an active low signal
    0=Output enable; 1=Output disable
  [9] ABE_MCBSP2_DR_OFFMODEENABLE rw — OffMode mode override control for pad abe_mcbsp2_dr
    values as CONTROL_CORE_PAD0_USBB1_HSIC_STROBE_PAD1_USBC1_ICUSB_DP.USBC1_ICUSB_DP_OFFMODEENABLE
  [8] ABE_MCBSP2_DR_INPUTENABLE rw — Input enable value for pad abe_mcbsp2_dr
    values as CONTROL_CORE_PAD0_USBB1_HSIC_STROBE_PAD1_USBC1_ICUSB_DP.USBC1_ICUSB_DP_INPUTENABLE
  [4] ABE_MCBSP2_DR_PULLTYPESELECT rw — pullup/down selection for pad abe_mcbsp2_dr
    0=pulldown selected; 1=pullup selected
  [3] ABE_MCBSP2_DR_PULLUDENABLE rw — pullup/down enable for pad abe_mcbsp2_dr
    0=pullup/down disabled; 1=pullup/down enabled
  [2:0] ABE_MCBSP2_DR_MUXMODE rw — Functional multiplexing selection for pad abe_mcbsp2_dr
    0=Select abe_mcbsp2_dr; 1=Select mcspi2_somi; 2=Select abe_mcasp_axr; 3=Select gpio_111; 4=Select usbb2_mm_rxdp; 7=Select safe_mode
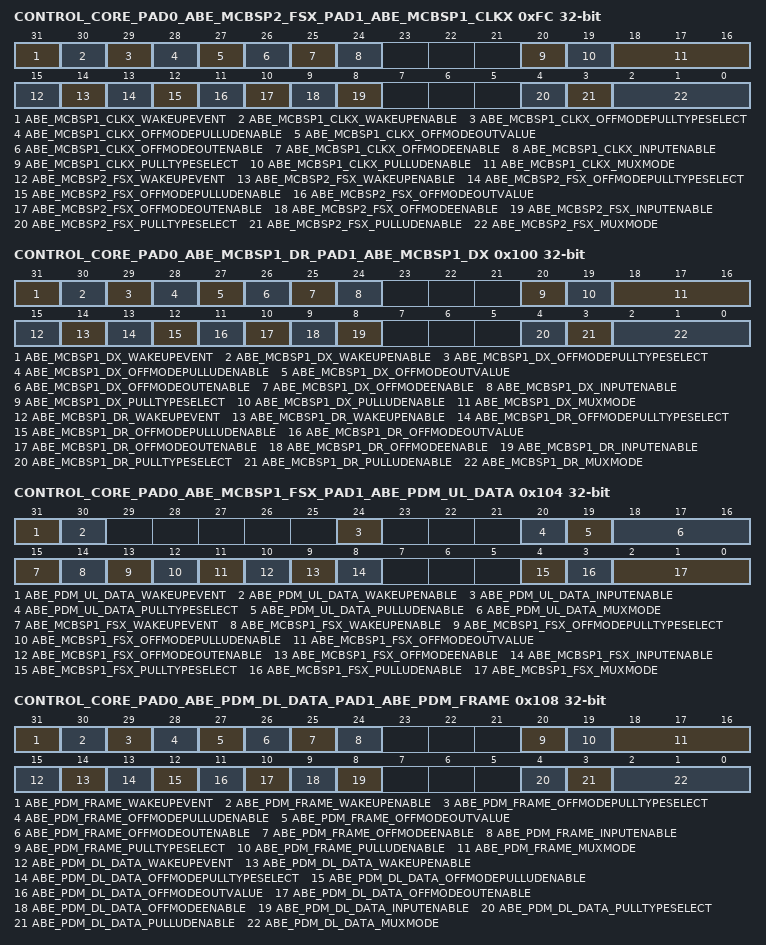
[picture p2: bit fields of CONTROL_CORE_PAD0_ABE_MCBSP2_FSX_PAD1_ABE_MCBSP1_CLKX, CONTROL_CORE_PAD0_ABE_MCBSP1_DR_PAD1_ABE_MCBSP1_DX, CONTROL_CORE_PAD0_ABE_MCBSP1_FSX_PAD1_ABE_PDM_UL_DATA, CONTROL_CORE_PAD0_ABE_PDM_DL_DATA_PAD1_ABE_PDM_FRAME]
0xFC CONTROL_CORE_PAD0_ABE_MCBSP2_FSX_PAD1_ABE_MCBSP1_CLKX — Register control for Pads abe_mcbsp2_fsx and abe_mcbsp1_clkx Access conditions. Read: unrestricted, Write: unrestricted
  [31] ABE_MCBSP1_CLKX_WAKEUPEVENT ro — Pad_x wake-up event status latched in the IO
    0=ABE_MCBSP1_CLKX_WAKEUPEVENT_0_r (No wake-up event occurred); 1=ABE_MCBSP1_CLKX_WAKEUPEVENT_1_r (A wake-up event occurred)
  [30] ABE_MCBSP1_CLKX_WAKEUPENABLE rw — Input pad wake-up enable (and OFF mode input enable value)
    values as CONTROL_CORE_PAD0_USBB1_HSIC_STROBE_PAD1_USBC1_ICUSB_DP.USBC1_ICUSB_DP_WAKEUPENABLE
  [29] ABE_MCBSP1_CLKX_OFFMODEPULLTYPESELECT rw — OffMode mode pullup/down selection for pad abe_mcbsp1_clkx
    0=Offmode pulldown selected; 1=Offmode pullup selected
  [28] ABE_MCBSP1_CLKX_OFFMODEPULLUDENABLE rw — OffMode mode pullup/down enable for pad abe_mcbsp1_clkx
    values as CONTROL_CORE_PAD0_USBB1_HSIC_STROBE_PAD1_USBC1_ICUSB_DP.USBC1_ICUSB_DP_OFFMODEPULLUDENABLE
  [27] ABE_MCBSP1_CLKX_OFFMODEOUTVALUE rw — OffMode mode output value for pad abe_mcbsp1_clkx
    0=Set value at 0; 1=Set value at 1
  [26] ABE_MCBSP1_CLKX_OFFMODEOUTENABLE rw — OffMode mode output enable value for pad abe_mcbsp1_clkx. This is an active low signal
    0=Output enable; 1=Output disable
  [25] ABE_MCBSP1_CLKX_OFFMODEENABLE rw — OffMode mode override control for pad abe_mcbsp1_clkx
    values as CONTROL_CORE_PAD0_USBB1_HSIC_STROBE_PAD1_USBC1_ICUSB_DP.USBC1_ICUSB_DP_OFFMODEENABLE
  [24] ABE_MCBSP1_CLKX_INPUTENABLE rw — Input enable value for pad abe_mcbsp1_clkx
    values as CONTROL_CORE_PAD0_USBB1_HSIC_STROBE_PAD1_USBC1_ICUSB_DP.USBC1_ICUSB_DP_INPUTENABLE
  [20] ABE_MCBSP1_CLKX_PULLTYPESELECT rw — pullup/down selection for pad abe_mcbsp1_clkx
    0=pulldown selected; 1=pullup selected
  [19] ABE_MCBSP1_CLKX_PULLUDENABLE rw — pullup/down enable for pad abe_mcbsp1_clkx
    0=pullup/down disabled; 1=pullup/down enabled
  [18:16] ABE_MCBSP1_CLKX_MUXMODE rw — Functional multiplexing selection for pad abe_mcbsp1_clkx
    0=Select abe_mcbsp1_clkx; 1=Select abe_slimbus1_clock; 3=Select gpio_114; 7=Select safe_mode
  [15] ABE_MCBSP2_FSX_WAKEUPEVENT ro — Pad_x wake-up event status latched in the IO
    0=ABE_MCBSP2_FSX_WAKEUPEVENT_0_r (No wake-up event occurred); 1=ABE_MCBSP2_FSX_WAKEUPEVENT_1_r (A wake-up event occurred)
  [14] ABE_MCBSP2_FSX_WAKEUPENABLE rw — Input pad wake-up enable (and OFF mode input enable value)
    values as CONTROL_CORE_PAD0_USBB1_HSIC_STROBE_PAD1_USBC1_ICUSB_DP.USBC1_ICUSB_DP_WAKEUPENABLE
  [13] ABE_MCBSP2_FSX_OFFMODEPULLTYPESELECT rw — OffMode mode pullup/down selection for pad abe_mcbsp2_fsx
    0=Offmode pulldown selected; 1=Offmode pullup selected
  [12] ABE_MCBSP2_FSX_OFFMODEPULLUDENABLE rw — OffMode mode pullup/down enable for pad abe_mcbsp2_fsx
    values as CONTROL_CORE_PAD0_USBB1_HSIC_STROBE_PAD1_USBC1_ICUSB_DP.USBC1_ICUSB_DP_OFFMODEPULLUDENABLE
  [11] ABE_MCBSP2_FSX_OFFMODEOUTVALUE rw — OffMode mode output value for pad abe_mcbsp2_fsx
    0=Set value at 0; 1=Set value at 1
  [10] ABE_MCBSP2_FSX_OFFMODEOUTENABLE rw — OffMode mode output enable value for pad abe_mcbsp2_fsx. This is an active low signal
    0=Output enable; 1=Output disable
  [9] ABE_MCBSP2_FSX_OFFMODEENABLE rw — OffMode mode override control for pad abe_mcbsp2_fsx
    values as CONTROL_CORE_PAD0_USBB1_HSIC_STROBE_PAD1_USBC1_ICUSB_DP.USBC1_ICUSB_DP_OFFMODEENABLE
  [8] ABE_MCBSP2_FSX_INPUTENABLE rw — Input enable value for pad abe_mcbsp2_fsx
    values as CONTROL_CORE_PAD0_USBB1_HSIC_STROBE_PAD1_USBC1_ICUSB_DP.USBC1_ICUSB_DP_INPUTENABLE
  [4] ABE_MCBSP2_FSX_PULLTYPESELECT rw — pullup/down selection for pad abe_mcbsp2_fsx
    0=pulldown selected; 1=pullup selected
  [3] ABE_MCBSP2_FSX_PULLUDENABLE rw — pullup/down enable for pad abe_mcbsp2_fsx
    0=pullup/down disabled; 1=pullup/down enabled
  [2:0] ABE_MCBSP2_FSX_MUXMODE rw — Functional multiplexing selection for pad abe_mcbsp2_fsx
    0=Select abe_mcbsp2_fsx; 1=Select mcspi2_cs0; 2=Select abe_mcasp_afsx; 3=Select gpio_113; 4=Select usbb2_mm_txen; 7=Select safe_mode
0x100 CONTROL_CORE_PAD0_ABE_MCBSP1_DR_PAD1_ABE_MCBSP1_DX — Register control for Pads abe_mcbsp1_dr and abe_mcbsp1_dx Access conditions. Read: unrestricted, Write: unrestricted
  [31] ABE_MCBSP1_DX_WAKEUPEVENT ro — Pad_x wake-up event status latched in the IO
    0=ABE_MCBSP1_DX_WAKEUPEVENT_0_r (No wake-up event occurred); 1=ABE_MCBSP1_DX_WAKEUPEVENT_1_r (A wake-up event occurred)
  [30] ABE_MCBSP1_DX_WAKEUPENABLE rw — Input pad wake-up enable (and OFF mode input enable value)
    values as CONTROL_CORE_PAD0_USBB1_HSIC_STROBE_PAD1_USBC1_ICUSB_DP.USBC1_ICUSB_DP_WAKEUPENABLE
  [29] ABE_MCBSP1_DX_OFFMODEPULLTYPESELECT rw — OffMode mode pullup/down selection for pad abe_mcbsp1_dx
    0=Offmode pulldown selected; 1=Offmode pullup selected
  [28] ABE_MCBSP1_DX_OFFMODEPULLUDENABLE rw — OffMode mode pullup/down enable for pad abe_mcbsp1_dx
    values as CONTROL_CORE_PAD0_USBB1_HSIC_STROBE_PAD1_USBC1_ICUSB_DP.USBC1_ICUSB_DP_OFFMODEPULLUDENABLE
  [27] ABE_MCBSP1_DX_OFFMODEOUTVALUE rw — OffMode mode output value for pad abe_mcbsp1_dx
    0=Set value at 0; 1=Set value at 1
  [26] ABE_MCBSP1_DX_OFFMODEOUTENABLE rw — OffMode mode output enable value for pad abe_mcbsp1_dx. This is an active low signal
    0=Output enable; 1=Output disable
  [25] ABE_MCBSP1_DX_OFFMODEENABLE rw — OffMode mode override control for pad abe_mcbsp1_dx
    values as CONTROL_CORE_PAD0_USBB1_HSIC_STROBE_PAD1_USBC1_ICUSB_DP.USBC1_ICUSB_DP_OFFMODEENABLE
  [24] ABE_MCBSP1_DX_INPUTENABLE rw — Input enable value for pad abe_mcbsp1_dx
    values as CONTROL_CORE_PAD0_USBB1_HSIC_STROBE_PAD1_USBC1_ICUSB_DP.USBC1_ICUSB_DP_INPUTENABLE
  [20] ABE_MCBSP1_DX_PULLTYPESELECT rw — pullup/down selection for pad abe_mcbsp1_dx
    0=pulldown selected; 1=pullup selected
  [19] ABE_MCBSP1_DX_PULLUDENABLE rw — pullup/down enable for pad abe_mcbsp1_dx
    0=pullup/down disabled; 1=pullup/down enabled
  [18:16] ABE_MCBSP1_DX_MUXMODE rw — Functional multiplexing selection for pad abe_mcbsp1_dx
    0=Select abe_mcbsp1_dx; 1=Select sdmmc3_dat2; 2=Select abe_mcasp_aclkx; 3=Select gpio_116; 7=Select safe_mode
  [15] ABE_MCBSP1_DR_WAKEUPEVENT ro — Pad_x wake-up event status latched in the IO
    0=ABE_MCBSP1_DR_WAKEUPEVENT_0_r (No wake-up event occurred); 1=ABE_MCBSP1_DR_WAKEUPEVENT_1_r (A wake-up event occurred)
  [14] ABE_MCBSP1_DR_WAKEUPENABLE rw — Input pad wake-up enable (and OFF mode input enable value)
    values as CONTROL_CORE_PAD0_USBB1_HSIC_STROBE_PAD1_USBC1_ICUSB_DP.USBC1_ICUSB_DP_WAKEUPENABLE
  [13] ABE_MCBSP1_DR_OFFMODEPULLTYPESELECT rw — OffMode mode pullup/down selection for pad abe_mcbsp1_dr
    0=Offmode pulldown selected; 1=Offmode pullup selected
  [12] ABE_MCBSP1_DR_OFFMODEPULLUDENABLE rw — OffMode mode pullup/down enable for pad abe_mcbsp1_dr
    values as CONTROL_CORE_PAD0_USBB1_HSIC_STROBE_PAD1_USBC1_ICUSB_DP.USBC1_ICUSB_DP_OFFMODEPULLUDENABLE
  [11] ABE_MCBSP1_DR_OFFMODEOUTVALUE rw — OffMode mode output value for pad abe_mcbsp1_dr
    0=Set value at 0; 1=Set value at 1
  [10] ABE_MCBSP1_DR_OFFMODEOUTENABLE rw — OffMode mode output enable value for pad abe_mcbsp1_dr. This is an active low signal
    0=Output enable; 1=Output disable
  [9] ABE_MCBSP1_DR_OFFMODEENABLE rw — OffMode mode override control for pad abe_mcbsp1_dr
    values as CONTROL_CORE_PAD0_USBB1_HSIC_STROBE_PAD1_USBC1_ICUSB_DP.USBC1_ICUSB_DP_OFFMODEENABLE
  [8] ABE_MCBSP1_DR_INPUTENABLE rw — Input enable value for pad abe_mcbsp1_dr
    values as CONTROL_CORE_PAD0_USBB1_HSIC_STROBE_PAD1_USBC1_ICUSB_DP.USBC1_ICUSB_DP_INPUTENABLE
  [4] ABE_MCBSP1_DR_PULLTYPESELECT rw — pullup/down selection for pad abe_mcbsp1_dr
    0=pulldown selected; 1=pullup selected
  [3] ABE_MCBSP1_DR_PULLUDENABLE rw — pullup/down enable for pad abe_mcbsp1_dr
    0=pullup/down disabled; 1=pullup/down enabled
  [2:0] ABE_MCBSP1_DR_MUXMODE rw — Functional multiplexing selection for pad abe_mcbsp1_dr
    0=Select abe_mcbsp1_dr; 1=Select abe_slimbus1_data; 3=Select gpio_115; 7=Select safe_mode
0x104 CONTROL_CORE_PAD0_ABE_MCBSP1_FSX_PAD1_ABE_PDM_UL_DATA — Register control for Pads abe_mcbsp1_fsx and abe_pdm_ul_data Access conditions. Read: unrestricted, Write: unrestricted
  [31] ABE_PDM_UL_DATA_WAKEUPEVENT ro — Pad_x wake-up event status latched in the IO
    0=ABE_PDM_UL_DATA_WAKEUPEVENT_0_r (No wake-up event occurred); 1=ABE_PDM_UL_DATA_WAKEUPEVENT_1_r (A wake-up event occurred)
  [30] ABE_PDM_UL_DATA_WAKEUPENABLE rw — Input pad wake-up enable (and OFF mode input enable value)
    values as CONTROL_CORE_PAD0_USBB1_HSIC_STROBE_PAD1_USBC1_ICUSB_DP.USBC1_ICUSB_DP_WAKEUPENABLE
  [24] ABE_PDM_UL_DATA_INPUTENABLE rw — Input enable value for pad abe_pdm_ul_data
    values as CONTROL_CORE_PAD0_USBB1_HSIC_STROBE_PAD1_USBC1_ICUSB_DP.USBC1_ICUSB_DP_INPUTENABLE
  [20] ABE_PDM_UL_DATA_PULLTYPESELECT rw — pullup/down selection for pad abe_pdm_ul_data
    0=pulldown selected; 1=pullup selected
  [19] ABE_PDM_UL_DATA_PULLUDENABLE rw — pullup/down enable for pad abe_pdm_ul_data
    0=pullup/down disabled; 1=pullup/down enabled
  [18:16] ABE_PDM_UL_DATA_MUXMODE rw — Functional multiplexing selection for pad abe_pdm_ul_data
    0=Select abe_pdm_ul_data; 1=Select abe_mcbsp3_dr; 7=Select safe_mode
  [15] ABE_MCBSP1_FSX_WAKEUPEVENT ro — Pad_x wake-up event status latched in the IO
    0=ABE_MCBSP1_FSX_WAKEUPEVENT_0_r (No wake-up event occurred); 1=ABE_MCBSP1_FSX_WAKEUPEVENT_1_r (A wake-up event occurred)
  [14] ABE_MCBSP1_FSX_WAKEUPENABLE rw — Input pad wake-up enable (and OFF mode input enable value)
    values as CONTROL_CORE_PAD0_USBB1_HSIC_STROBE_PAD1_USBC1_ICUSB_DP.USBC1_ICUSB_DP_WAKEUPENABLE
  [13] ABE_MCBSP1_FSX_OFFMODEPULLTYPESELECT rw — OffMode mode pullup/down selection for pad abe_mcbsp1_fsx
    0=Offmode pulldown selected; 1=Offmode pullup selected
  [12] ABE_MCBSP1_FSX_OFFMODEPULLUDENABLE rw — OffMode mode pullup/down enable for pad abe_mcbsp1_fsx
    values as CONTROL_CORE_PAD0_USBB1_HSIC_STROBE_PAD1_USBC1_ICUSB_DP.USBC1_ICUSB_DP_OFFMODEPULLUDENABLE
  [11] ABE_MCBSP1_FSX_OFFMODEOUTVALUE rw — OffMode mode output value for pad abe_mcbsp1_fsx
    0=Set value at 0; 1=Set value at 1
  [10] ABE_MCBSP1_FSX_OFFMODEOUTENABLE rw — OffMode mode output enable value for pad abe_mcbsp1_fsx. This is an active low signal
    0=Output enable; 1=Output disable
  [9] ABE_MCBSP1_FSX_OFFMODEENABLE rw — OffMode mode override control for pad abe_mcbsp1_fsx
    values as CONTROL_CORE_PAD0_USBB1_HSIC_STROBE_PAD1_USBC1_ICUSB_DP.USBC1_ICUSB_DP_OFFMODEENABLE
  [8] ABE_MCBSP1_FSX_INPUTENABLE rw — Input enable value for pad abe_mcbsp1_fsx
    values as CONTROL_CORE_PAD0_USBB1_HSIC_STROBE_PAD1_USBC1_ICUSB_DP.USBC1_ICUSB_DP_INPUTENABLE
  [4] ABE_MCBSP1_FSX_PULLTYPESELECT rw — pullup/down selection for pad abe_mcbsp1_fsx
    0=pulldown selected; 1=pullup selected
  [3] ABE_MCBSP1_FSX_PULLUDENABLE rw — pullup/down enable for pad abe_mcbsp1_fsx
    0=pullup/down disabled; 1=pullup/down enabled
  [2:0] ABE_MCBSP1_FSX_MUXMODE rw — Functional multiplexing selection for pad abe_mcbsp1_fsx
    0=Select abe_mcbsp1_fsx; 1=Select sdmmc3_dat3; 2=Select abe_mcasp_amutein; 3=Select gpio_117; 7=Select safe_mode
0x108 CONTROL_CORE_PAD0_ABE_PDM_DL_DATA_PAD1_ABE_PDM_FRAME — Register control for Pads abe_pdm_dl_data and abe_pdm_frame Access conditions. Read: unrestricted, Write: unrestricted
  [31] ABE_PDM_FRAME_WAKEUPEVENT ro — Pad_x wake-up event status latched in the IO
    0=ABE_PDM_FRAME_WAKEUPEVENT_0_r (No wake-up event occurred); 1=ABE_PDM_FRAME_WAKEUPEVENT_1_r (A wake-up event occurred)
  [30] ABE_PDM_FRAME_WAKEUPENABLE rw — Input pad wake-up enable (and OFF mode input enable value)
    values as CONTROL_CORE_PAD0_USBB1_HSIC_STROBE_PAD1_USBC1_ICUSB_DP.USBC1_ICUSB_DP_WAKEUPENABLE
  [29] ABE_PDM_FRAME_OFFMODEPULLTYPESELECT rw — OffMode mode pullup/down selection for pad abe_pdm_frame
    0=Offmode pulldown selected; 1=Offmode pullup selected
  [28] ABE_PDM_FRAME_OFFMODEPULLUDENABLE rw — OffMode mode pullup/down enable for pad abe_pdm_frame
    values as CONTROL_CORE_PAD0_USBB1_HSIC_STROBE_PAD1_USBC1_ICUSB_DP.USBC1_ICUSB_DP_OFFMODEPULLUDENABLE
  [27] ABE_PDM_FRAME_OFFMODEOUTVALUE rw — OffMode mode output value for pad abe_pdm_frame
    0=Set value at 0; 1=Set value at 1
  [26] ABE_PDM_FRAME_OFFMODEOUTENABLE rw — OffMode mode output enable value for pad abe_pdm_frame. This is an active low signal
    0=Output enable; 1=Output disable
  [25] ABE_PDM_FRAME_OFFMODEENABLE rw — OffMode mode override control for pad abe_pdm_frame
    values as CONTROL_CORE_PAD0_USBB1_HSIC_STROBE_PAD1_USBC1_ICUSB_DP.USBC1_ICUSB_DP_OFFMODEENABLE
  [24] ABE_PDM_FRAME_INPUTENABLE rw — Input enable value for pad abe_pdm_frame
    values as CONTROL_CORE_PAD0_USBB1_HSIC_STROBE_PAD1_USBC1_ICUSB_DP.USBC1_ICUSB_DP_INPUTENABLE
  [20] ABE_PDM_FRAME_PULLTYPESELECT rw — pullup/down selection for pad abe_pdm_frame
    0=pulldown selected; 1=pullup selected
  [19] ABE_PDM_FRAME_PULLUDENABLE rw — pullup/down enable for pad abe_pdm_frame
    0=pullup/down disabled; 1=pullup/down enabled
  [18:16] ABE_PDM_FRAME_MUXMODE rw — Functional multiplexing selection for pad abe_pdm_frame
    0=Select abe_pdm_frame; 1=Select abe_mcbsp3_clkx; 7=Select safe_mode
  [15] ABE_PDM_DL_DATA_WAKEUPEVENT ro — Pad_x wake-up event status latched in the IO
    0=ABE_PDM_DL_DATA_WAKEUPEVENT_0_r (No wake-up event occurred); 1=ABE_PDM_DL_DATA_WAKEUPEVENT_1_r (A wake-up event occurred)
  [14] ABE_PDM_DL_DATA_WAKEUPENABLE rw — Input pad wake-up enable (and OFF mode input enable value)
    values as CONTROL_CORE_PAD0_USBB1_HSIC_STROBE_PAD1_USBC1_ICUSB_DP.USBC1_ICUSB_DP_WAKEUPENABLE
  [13] ABE_PDM_DL_DATA_OFFMODEPULLTYPESELECT rw — OffMode mode pullup/down selection for pad abe_pdm_dl_data
    0=Offmode pulldown selected; 1=Offmode pullup selected
  [12] ABE_PDM_DL_DATA_OFFMODEPULLUDENABLE rw — OffMode mode pullup/down enable for pad abe_pdm_dl_data
    values as CONTROL_CORE_PAD0_USBB1_HSIC_STROBE_PAD1_USBC1_ICUSB_DP.USBC1_ICUSB_DP_OFFMODEPULLUDENABLE
  [11] ABE_PDM_DL_DATA_OFFMODEOUTVALUE rw — OffMode mode output value for pad abe_pdm_dl_data
    0=Set value at 0; 1=Set value at 1
  [10] ABE_PDM_DL_DATA_OFFMODEOUTENABLE rw — OffMode mode output enable value for pad abe_pdm_dl_data. This is an active low signal
    0=Output enable; 1=Output disable
  [9] ABE_PDM_DL_DATA_OFFMODEENABLE rw — OffMode mode override control for pad abe_pdm_dl_data
    values as CONTROL_CORE_PAD0_USBB1_HSIC_STROBE_PAD1_USBC1_ICUSB_DP.USBC1_ICUSB_DP_OFFMODEENABLE
  [8] ABE_PDM_DL_DATA_INPUTENABLE rw — Input enable value for pad abe_pdm_dl_data
    values as CONTROL_CORE_PAD0_USBB1_HSIC_STROBE_PAD1_USBC1_ICUSB_DP.USBC1_ICUSB_DP_INPUTENABLE
  [4] ABE_PDM_DL_DATA_PULLTYPESELECT rw — pullup/down selection for pad abe_pdm_dl_data
    0=pulldown selected; 1=pullup selected
  [3] ABE_PDM_DL_DATA_PULLUDENABLE rw — pullup/down enable for pad abe_pdm_dl_data
    0=pullup/down disabled; 1=pullup/down enabled
  [2:0] ABE_PDM_DL_DATA_MUXMODE rw — Functional multiplexing selection for pad abe_pdm_dl_data
    0=Select abe_pdm_dl_data; 1=Select abe_mcbsp3_dx; 7=Select safe_mode
